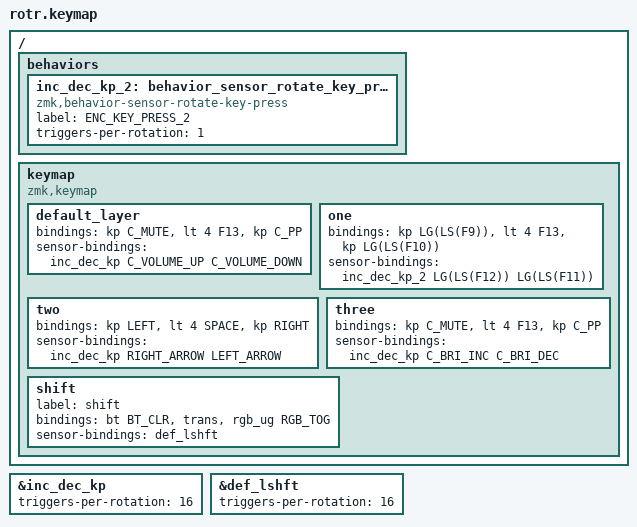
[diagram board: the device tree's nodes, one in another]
#include <behaviors.dtsi>
#include <dt-bindings/zmk/keys.h>
#include <dt-bindings/zmk/rgb.h>
#include <dt-bindings/zmk/bt.h>

/ {
    behaviors {
        inc_dec_kp_2: behavior_sensor_rotate_key_press_2 {
            compatible = "zmk,behavior-sensor-rotate-key-press";
            label = "ENC_KEY_PRESS_2";
            triggers-per-rotation = <1>;
            #sensor-binding-cells = <1>;
            
        };
    };
};


&inc_dec_kp {
	triggers-per-rotation = <16>;
};
&def_lshft {
	triggers-per-rotation = <16>;
};

/ {
	keymap {
		compatible = "zmk,keymap";

		default_layer {
			//PREV | PLAY/PAUSE | NEXT
			bindings = <&kp C_MUTE &lt 4 F13 &kp C_PP>;
			sensor-bindings = <&inc_dec_kp C_VOLUME_UP C_VOLUME_DOWN>;
		};
		one {
			//PREV | PLAY/PAUSE | NEXT
			bindings = <&kp LG(LS(F9)) &lt 4 F13 &kp LG(LS(F10))>;
			sensor-bindings = <&inc_dec_kp_2 LG(LS(F12)) LG(LS(F11))>;
		};
		two {
			//PREV | PLAY/PAUSE | NEXT
			bindings = <&kp LEFT &lt 4 SPACE &kp RIGHT>;
			sensor-bindings = <&inc_dec_kp RIGHT_ARROW LEFT_ARROW>;
		};
		three {
			//PREV | PLAY/PAUSE | NEXT
			bindings = <&kp C_MUTE &lt 4 F13 &kp C_PP>;
			sensor-bindings = <&inc_dec_kp C_BRI_INC C_BRI_DEC>;
		};
		shift {
			label = "shift";
			//PREV | PLAY/PAUSE | NEXT
			bindings = <&bt BT_CLR &trans &rgb_ug RGB_TOG>;
			sensor-bindings = <&def_lshft>;
		};
	};
};
